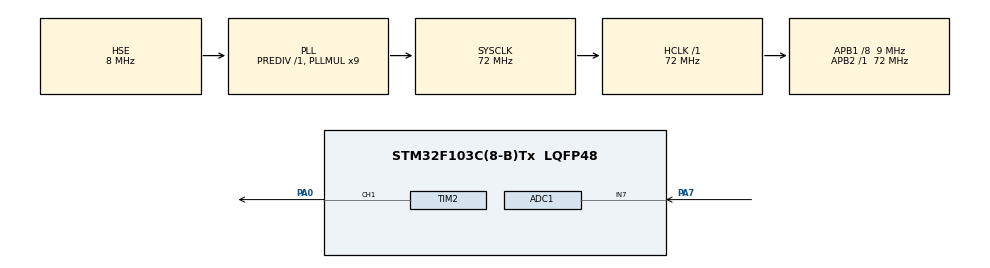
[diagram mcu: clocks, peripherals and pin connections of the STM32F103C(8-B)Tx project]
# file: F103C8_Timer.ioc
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ADC1.Channel-2\#ChannelRegularConversion=ADC_CHANNEL_7
ADC1.NbrOfConversionFlag=1
ADC1.Rank-2\#ChannelRegularConversion=1
ADC1.SamplingTime-2\#ChannelRegularConversion=ADC_SAMPLETIME_1CYCLE_5
ADC1.master=1
Mcu.Family=STM32F1
Mcu.Name=STM32F103C(8-B)Tx
Mcu.Package=LQFP48
NVIC.PriorityGroup=NVIC_PRIORITYGROUP_4
NVIC.TIM2_IRQn=true\:0\:0\:false\:false\:true\:true\:true
PA0-WKUP.Signal=S_TIM2_CH1_ETR
PA13.Mode=Serial_Wire
PA13.Signal=SYS_JTMS-SWDIO
PA14.Mode=Serial_Wire
PA14.Signal=SYS_JTCK-SWCLK
PA7.Signal=ADCx_IN7
PD0-OSC_IN.Mode=HSE-External-Oscillator
PD0-OSC_IN.Signal=RCC_OSC_IN
PD1-OSC_OUT.Mode=HSE-External-Oscillator
PD1-OSC_OUT.Signal=RCC_OSC_OUT
ProjectManager.HeapSize=0x200
ProjectManager.StackSize=0x400
ProjectManager.TargetToolchain=STM32CubeIDE
RCC.ADCPresc=RCC_ADCPCLK2_DIV6
RCC.AHBFreq_Value=72000000
RCC.APB1CLKDivider=RCC_HCLK_DIV8
RCC.APB1Freq_Value=9000000
RCC.APB1TimFreq_Value=18000000
RCC.APB2Freq_Value=72000000
RCC.APB2TimFreq_Value=72000000
RCC.HCLKFreq_Value=72000000
RCC.PLLMUL=RCC_PLL_MUL9
RCC.PLLSourceVirtual=RCC_PLLSOURCE_HSE
RCC.SYSCLKFreq_VALUE=72000000
RCC.SYSCLKSource=RCC_SYSCLKSOURCE_PLLCLK
RCC.USBFreq_Value=72000000
SH.ADCx_IN7.0=ADC1_IN7,IN7
SH.S_TIM2_CH1_ETR.0=TIM2_CH1,Output Compare1 CH1
TIM2.AutoReloadPreload=TIM_AUTORELOAD_PRELOAD_ENABLE
TIM2.Channel-Output\ Compare1\ CH1=TIM_CHANNEL_1
TIM2.OC1Preload=ENABLE
TIM2.OCMode_1=TIM_OCMODE_TOGGLE
TIM2.Prescaler=200
TIM2.Pulse-Output\ Compare1\ CH1=255
VP_TIM2_VS_ClockSourceINT.Mode=Internal
board=custom

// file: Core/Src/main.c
/* USER CODE BEGIN Header */

/* F103C8_Timer
 * Manipulação do Timer 2 do microcontrolador STM32F103C8 para
 * explorar as funcionalidades desse periférico, como interrupção
 * por overflow, captura/comparação com forma de onda em canal de
 * saída.  */

/**
  ******************************************************************************
  * @file           : main.c
  * @brief          : Main program body
  ******************************************************************************
  * @attention
  *
  * <h2><center>&copy; Copyright (c) 2020 STMicroelectronics.
  * All rights reserved.</center></h2>
  *
  * This software component is licensed by ST under BSD 3-Clause license,
  * the "License"; You may not use this file except in compliance with the
  * License. You may obtain a copy of the License at:
  *                        opensource.org/licenses/BSD-3-Clause
  *
  ******************************************************************************
  */
/* USER CODE END Header */
#include "main.h"

/* USER CODE BEGIN PD */
#define CONVERT_AD_TIMER	16	//Fator de conversão 12 bits para 16 bits
/* USER CODE END PD */

ADC_HandleTypeDef hadc1;

TIM_HandleTypeDef htim2;

/* USER CODE BEGIN PV */
uint32_t read_adc=0;
/* USER CODE END PV */

void SystemClock_Config(void);
static void MX_GPIO_Init(void);
static void MX_TIM2_Init(void);
static void MX_ADC1_Init(void);

int main(void)
{

  /* MCU Configuration--------------------------------------------------------*/

  /* Reset of all peripherals, Initializes the Flash interface and the Systick. */
  HAL_Init();

  /* Configure the system clock */
  SystemClock_Config();

  /* USER CODE BEGIN SysInit */
  /* Clock do sistema: 72 MHz. Testes com 8 MHz mostraram que o timer não operou adequadamente. */
  /* USER CODE END SysInit */

  /* Initialize all configured peripherals */
  MX_GPIO_Init();
  MX_TIM2_Init();
  MX_ADC1_Init();
  /* USER CODE BEGIN 2 */
  htim2.Instance->CR1 |= 0x01; //Habilita o timer 2
  HAL_TIM_OC_Start(&htim2, TIM_CHANNEL_1); //Inicia a geração da forma de onda por modo de comparação

  /* Foi necessário habilitar o preload dos registradores ARR e CCR1
   * para uma operação adequada do projeto. Sem o preload, observou-se que
   * o LED apresentou mau funcionamento devido à instabilidade da forma de onda
   * no canal de saída do timer. Isso ocorreu devido à operação mal coordenada
   * entre conversão AD e atualização dos registradores ARR e CCR1. O uso do preload
   * garantiu a atualização desses registradores somente após o update event (UEV),
   * eliminando interferência com o AD.   */

  //Alterar manualmente Auto Reload Register e Capture/Compare Register (canal 1)
  /*htim2.Instance->ARR = 0x57FF;
  htim2.Instance->CCR1 = 0xFF5;*/
  /* USER CODE END 2 */

  /* Infinite loop */
  while (1)
  {

    /* USER CODE BEGIN 3 */
	  //HAL_TIM_OC_Start(&htim2, TIM_CHANNEL_1);
	  /*Não é necessário incluir a função novamente no loop,
	  pois o processador trata a a geração do sinal por
	  comparação automaticamente. */

	  //Leitura do AD
	  HAL_ADC_Start(&hadc1); //início da conversão
	  read_adc = HAL_ADC_GetValue(&hadc1);	//leitura

	  //Atualização do timer
	  htim2.Instance->ARR = read_adc*CONVERT_AD_TIMER;
	  //Se read_adc é não-nulo, atribui-se o valor do ARR dividido por 4
	  //ao registrador de comparação
	  if(read_adc)
		  htim2.Instance->CCR1 = htim2.Instance->ARR/4;
	  else{
		  htim2.Instance->ARR = read_adc+10;
		  htim2.Instance->CCR1 = htim2.Instance->ARR/2;
	  }

  }
  /* USER CODE END 3 */
}

void SystemClock_Config(void)
{
  RCC_OscInitTypeDef RCC_OscInitStruct = {0};
  RCC_ClkInitTypeDef RCC_ClkInitStruct = {0};
  RCC_PeriphCLKInitTypeDef PeriphClkInit = {0};

  /** Initializes the RCC Oscillators according to the specified parameters
  * in the RCC_OscInitTypeDef structure.
  */
  RCC_OscInitStruct.OscillatorType = RCC_OSCILLATORTYPE_HSE;
  RCC_OscInitStruct.HSEState = RCC_HSE_ON;
  RCC_OscInitStruct.HSEPredivValue = RCC_HSE_PREDIV_DIV1;
  RCC_OscInitStruct.HSIState = RCC_HSI_ON;
  RCC_OscInitStruct.PLL.PLLState = RCC_PLL_ON;
  RCC_OscInitStruct.PLL.PLLSource = RCC_PLLSOURCE_HSE;
  RCC_OscInitStruct.PLL.PLLMUL = RCC_PLL_MUL9;
  if (HAL_RCC_OscConfig(&RCC_OscInitStruct) != HAL_OK)
  {
    Error_Handler();
  }
  /** Initializes the CPU, AHB and APB buses clocks
  */
  RCC_ClkInitStruct.ClockType = RCC_CLOCKTYPE_HCLK|RCC_CLOCKTYPE_SYSCLK
                              |RCC_CLOCKTYPE_PCLK1|RCC_CLOCKTYPE_PCLK2;
  RCC_ClkInitStruct.SYSCLKSource = RCC_SYSCLKSOURCE_PLLCLK;
  RCC_ClkInitStruct.AHBCLKDivider = RCC_SYSCLK_DIV1;
  RCC_ClkInitStruct.APB1CLKDivider = RCC_HCLK_DIV8;
  RCC_ClkInitStruct.APB2CLKDivider = RCC_HCLK_DIV1;

  if (HAL_RCC_ClockConfig(&RCC_ClkInitStruct, FLASH_LATENCY_2) != HAL_OK)
  {
    Error_Handler();
  }
  PeriphClkInit.PeriphClockSelection = RCC_PERIPHCLK_ADC;
  PeriphClkInit.AdcClockSelection = RCC_ADCPCLK2_DIV6;
  if (HAL_RCCEx_PeriphCLKConfig(&PeriphClkInit) != HAL_OK)
  {
    Error_Handler();
  }
}

static void MX_ADC1_Init(void)
{

  ADC_ChannelConfTypeDef sConfig = {0};

  /** Common config
  */
  hadc1.Instance = ADC1;
  hadc1.Init.ScanConvMode = ADC_SCAN_DISABLE;
  hadc1.Init.ContinuousConvMode = DISABLE;
  hadc1.Init.DiscontinuousConvMode = DISABLE;
  hadc1.Init.ExternalTrigConv = ADC_SOFTWARE_START;
  hadc1.Init.DataAlign = ADC_DATAALIGN_RIGHT;
  hadc1.Init.NbrOfConversion = 1;
  if (HAL_ADC_Init(&hadc1) != HAL_OK)
  {
    Error_Handler();
  }
  /** Configure Regular Channel
  */
  sConfig.Channel = ADC_CHANNEL_7;
  sConfig.Rank = ADC_REGULAR_RANK_1;
  sConfig.SamplingTime = ADC_SAMPLETIME_1CYCLE_5;
  if (HAL_ADC_ConfigChannel(&hadc1, &sConfig) != HAL_OK)
  {
    Error_Handler();
  }
  /* USER CODE BEGIN ADC1_Init 2 */
  hadc1.Instance->CR1 |= 0x01; //Inicializa o conversor AD
  /* USER CODE END ADC1_Init 2 */

}

static void MX_TIM2_Init(void)
{

  TIM_ClockConfigTypeDef sClockSourceConfig = {0};
  TIM_MasterConfigTypeDef sMasterConfig = {0};
  TIM_OC_InitTypeDef sConfigOC = {0};

  htim2.Instance = TIM2;
  htim2.Init.Prescaler = 200;
  htim2.Init.CounterMode = TIM_COUNTERMODE_UP;
  htim2.Init.Period = 65535;
  htim2.Init.ClockDivision = TIM_CLOCKDIVISION_DIV1;
  htim2.Init.AutoReloadPreload = TIM_AUTORELOAD_PRELOAD_ENABLE;
  if (HAL_TIM_Base_Init(&htim2) != HAL_OK)
  {
    Error_Handler();
  }
  sClockSourceConfig.ClockSource = TIM_CLOCKSOURCE_INTERNAL;
  if (HAL_TIM_ConfigClockSource(&htim2, &sClockSourceConfig) != HAL_OK)
  {
    Error_Handler();
  }
  if (HAL_TIM_OC_Init(&htim2) != HAL_OK)
  {
    Error_Handler();
  }
  sMasterConfig.MasterOutputTrigger = TIM_TRGO_RESET;
  sMasterConfig.MasterSlaveMode = TIM_MASTERSLAVEMODE_DISABLE;
  if (HAL_TIMEx_MasterConfigSynchronization(&htim2, &sMasterConfig) != HAL_OK)
  {
    Error_Handler();
  }
  sConfigOC.OCMode = TIM_OCMODE_TOGGLE;
  sConfigOC.Pulse = 255;
  sConfigOC.OCPolarity = TIM_OCPOLARITY_HIGH;
  sConfigOC.OCFastMode = TIM_OCFAST_DISABLE;
  if (HAL_TIM_OC_ConfigChannel(&htim2, &sConfigOC, TIM_CHANNEL_1) != HAL_OK)
  {
    Error_Handler();
  }
  __HAL_TIM_ENABLE_OCxPRELOAD(&htim2, TIM_CHANNEL_1);
  /* USER CODE BEGIN TIM2_Init 2 */
  htim2.Instance->DIER |= 0x02;	//Habilita interrupção por captura/comparação do canal 1
  /* USER CODE END TIM2_Init 2 */
  HAL_TIM_MspPostInit(&htim2);

}

static void MX_GPIO_Init(void)
{

  /* GPIO Ports Clock Enable */
  __HAL_RCC_GPIOD_CLK_ENABLE();
  __HAL_RCC_GPIOA_CLK_ENABLE();

}

void Error_Handler(void)
{
  __disable_irq();
  while (1)
  {
  }
}

/************************ (C) COPYRIGHT STMicroelectronics *****END OF FILE****/
